# myChip register map
Vendor: ARM Ltd.; Series: ARMCM3; File version: 1.2
CPU: CM3 r2p1, little endian, no MPU, no FPU, 3 interrupt priority bits
Registers are 32-bit, read-write, reset 0x0 unless marked. A register's access mark holds for its fields unless they carry their own. Offsets are from the block's base; [hi:lo] are bit positions; {n}, {i} and the like mark numbered series.

## SYSCTRL
Base 0x40021000
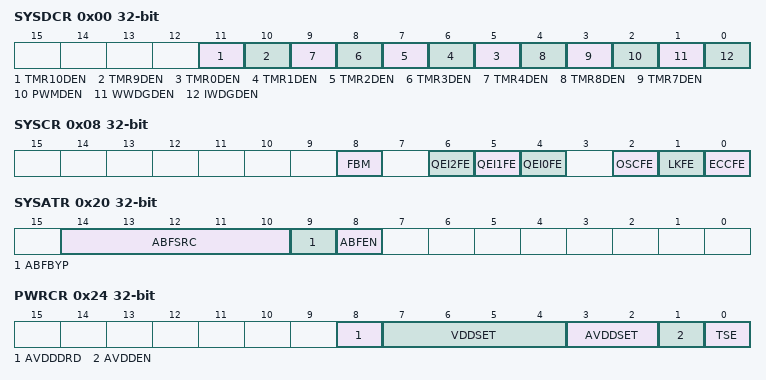
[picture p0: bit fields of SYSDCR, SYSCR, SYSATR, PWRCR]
0x00 SYSDCR — System Debug Config Register
  [11] TMR10DEN — TMR10调试使能(TMR10 Debug Enable)
  [10] TMR9DEN — TMR9调试使能(TMR9 Debug Enable)
  [n+5] TMR{n}DEN (n=0..4) — TMR{n}调试使能(TMR{n} Debug Enable)
  [4] TMR8DEN — TMR8调试使能(TMR8 Debug Enable)
  [3] TMR7DEN — TMR7调试使能(TMR7 Debug Enable)
  [2] PWMDEN — HRPWM调试使能(HRPWM Debug Enable)
  [1] WWDGDEN — WWDG调试使能(WWDG Debug Enable)
  [0] IWDGDEN — IWDG调试使能(IWDG Debug Enable)
0x08 SYSCR — System Config Register
  [8] FBM — FLASH双Bank映射切换(FLASH Double Bank Mapping)
  [6] QEI2FE — QEI2运行异常系统故障使能(QEI2 Fault Enable)
  [5] QEI1FE — QEI1运行异常系统故障使能(QEI1 Fault Enable)
  [4] QEI0FE — QEI0运行异常系统故障使能(QEI0 Fault Enable)
  [2] OSCFE — XOSC时钟异常系统故障使能(XOSC Loss Fault Enable)
  [1] LKFE — CPU Lockup系统故障使能(CPU Lockup Fault Enable)
  [0] ECCFE — FLASH多位ECC系统故障使能(FLASH nBits ECC Fault Enable)
0x0C DMARCR — DMA Request Config Register
  [31:19] DRCR — DMA请求选择控制位(DMA Request Config Enable)
0x20 SYSATR — System Analog Config Register
  [14:10] ABFSRC — ADC Buffer源选择(ADC Buffer Source Selection)
  [9] ABFBYP — ADC Buffer旁路使能(ADC Buffer Bypass Enable)
  [8] ABFEN — ADC Buffer使能(ADC Buffer Enable)
0x24 PWRCR — PMU Power Config Register
  [8] AVDDDRD — AVDD的无电容LDO下拉配置选择（AVDD Drop Down）
  [7:4] VDDSET — VDD电压控制(VDD Voltage Config)
  [3:2] AVDDSET — AVDD电压控制(AVDD Voltage Config)
  [1] AVDDEN — AVDD使能控制（AVDD Enable）
  [0] TSE — 温度传感器使能控制（Temperature Sensor Enable）
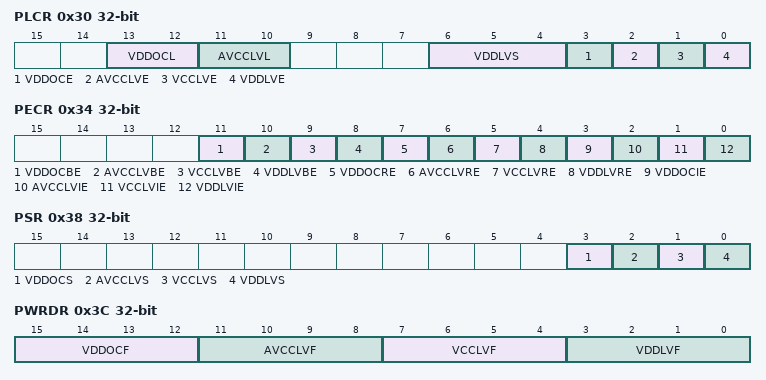
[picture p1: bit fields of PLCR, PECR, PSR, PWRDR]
0x30 PLCR — Power Limit Config Register
  [13:12] VDDOCL — VDD过流阈值设置(VDD OverCurrent Limit Config)
  [11:10] AVCCLVL — AVCC低电压阈值设置(AVCC LowVoltage Limit Config)
  [6:4] VDDLVS — VDD低电压阈值设置(VDD LowVoltage Limit Config)
  [3] VDDOCE — VDD过流监测使能(VDD OverCurrent Enable)
  [2] AVCCLVE — AVCC低电压监测使能(AVCC LowVoltage Enable)
  [1] VCCLVE — VCC低电压监测使能(VCC LowVoltage Enable)
  [0] VDDLVE — VDD低电压监测使能(VDD LowVoltage Enable)
0x34 PECR — Power Event Control Register
  [11] VDDOCBE — VDD过流刹车使能(VDD OverCurrent Brake Enable)
  [10] AVCCLVBE — AVCC低电压刹车使能(AVCC LowVoltage Brake Enable)
  [9] VCCLVBE — VCC低电压刹车使能(VCC LowVoltage Brake Enable)
  [8] VDDLVBE — VDD低电压刹车使能(VDD LowVoltage Brake Enable)
  [7] VDDOCRE — VDD过流复位使能(VDD OverCurrent Reset Enable)
  [6] AVCCLVRE — AVCC低电压复位使能(AVCC LowVoltage Reset Enable)
  [5] VCCLVRE — VCC低电压复位使能(VCC LowVoltage Reset Enable)
  [4] VDDLVRE — VDD低电压复位使能(VDD LowVoltage Reset Enable)
  [3] VDDOCIE — VDD过流中断使能(VDD OverCurrent Interrupt Enable)
  [2] AVCCLVIE — AVCC低电压中断使能(AVCC LowVoltage Interrupt Enable)
  [1] VCCLVIE — VCC低电压中断使能(VCC LowVoltage Interrupt Enable)
  [0] VDDLVIE — VDD低电压中断使能(VDD LowVoltage Interrupt Enable)
0x38 PSR — Power Status Register
  [3] VDDOCS ro — VDD过流状态位(VDD OverCurrent Status)
  [2] AVCCLVS ro — AVCC低电压状态位(AVCC LowVoltage Status)
  [1] VCCLVS ro — VCC低电压状态位(VCC LowVoltage Status)
  [0] VDDLVS ro — VDD低电压状态位(VDD LowVoltage Status)
0x3C PWRDR — Power Debounce Register
  [15:12] VDDOCF — VDD过流消抖配置(VDD OverCurrent Config)
  [11:8] AVCCLVF — AVCC欠压消抖配置(AVCC LowVoltage Config)
  [7:4] VCCLVF — VCC欠压消抖配置(VCC LowVoltage Config)
  [3:0] VDDLVF — VDD欠压消抖配置(VDD LowVoltage Config)
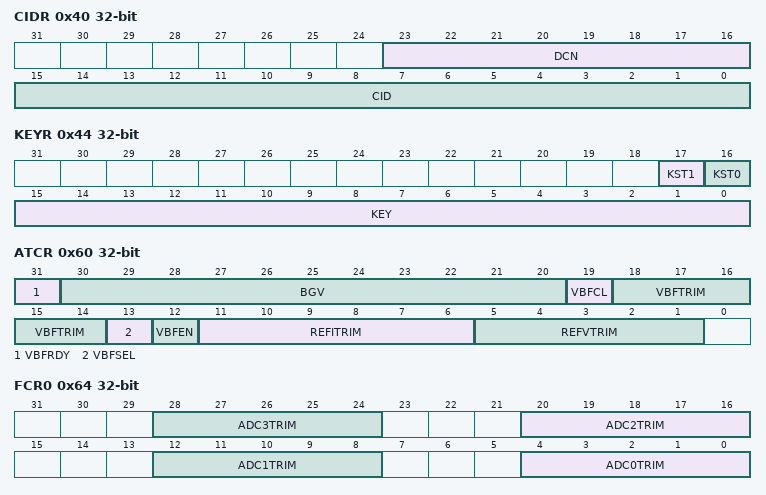
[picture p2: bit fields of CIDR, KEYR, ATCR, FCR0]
0x40 CIDR — System ChipId Config Register
  [23:16] DCN ro — CHIP DCN
  [15:0] CID ro — CHIP CID
0x44 KEYR — LockKey Register
  [17] KST1 — 校准寄存器保护状态位
  [16] KST0 — 系统寄存器保护状态位
  [15:0] KEY — 寄存器写保护(Register LockKey)
{0x50+4i} UID{i} (i=0..3) — System UserID{i} Register
  [31:0] UID{i} ro — System UID{i} Register
0x60 ATCR — Analog Trim Config Register
  [31] VBFRDY — VREFBUF输出电压状态
  [30:20] BGV — 内部BGR电压
  [19] VBFCL — VREFBUF启动限流使能
  [18:14] VBFTRIM — VREFBUF输出电压校准
  [13] VBFSEL — VREFBUF输出电压选择
  [12] VBFEN — VREFBUF使能
  [11:6] REFITRIM — REF参考电流校准
  [5:1] REFVTRIM — REF参考电压校准
0x64 FCR0 — System AutoLoad Register0
  [8n+4:8n] ADC{n}TRIM (n=0..3) — ADC{n}内部1/2VREF电压校准值
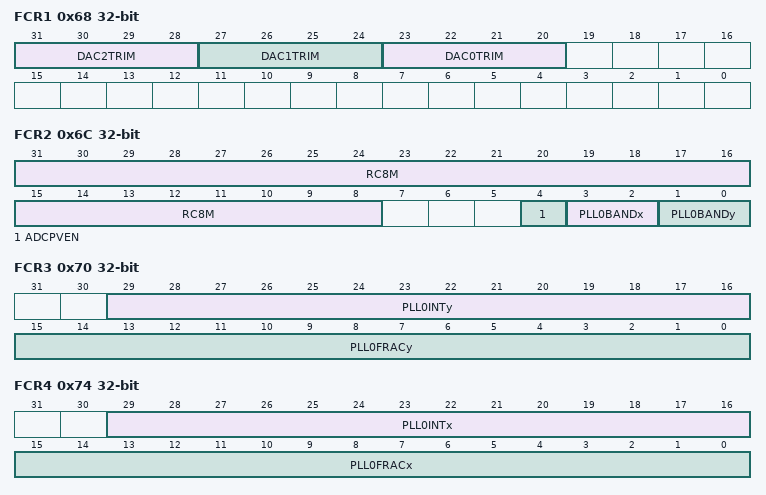
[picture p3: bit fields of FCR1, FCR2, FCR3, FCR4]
0x68 FCR1 — System AutoLoad Register1
  [31:28] DAC2TRIM — DAC2输出BUF Offset校准
  [27:24] DAC1TRIM — DAC1输出BUF Offset校准
  [23:20] DAC0TRIM — DAC0输出BUF Offset校准
0x6C FCR2 — System AutoLoad Register2
  [31:8] RC8M — RC8M实际频率
  [4] ADCPVEN — ADC转换相位时钟使能
  [3:2] PLL0BANDx — PLL0-180M校准BAND值
  [1:0] PLL0BANDy — PLL0-200M校准BAND值
0x70 FCR3 — System AutoLoad Register3
  [29:16] PLL0INTy — PLL0-200M校准分频INT值
  [15:0] PLL0FRACy — PLL0-200M校准分频FRAC值
0x74 FCR4 — System AutoLoad Register4
  [29:16] PLL0INTx — PLL0-180M校准分频INT值
  [15:0] PLL0FRACx — PLL0-180M校准分频FRAC值
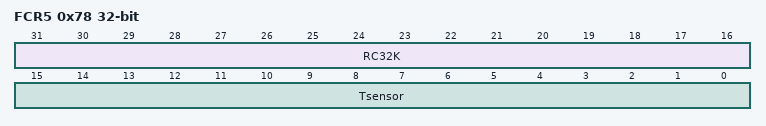
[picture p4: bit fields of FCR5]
0x78 FCR5 — System AutoLoad Register5
  [31:16] RC32K — RC32K实际频率
  [15:0] Tsensor — Tsensor温度传感校准值
